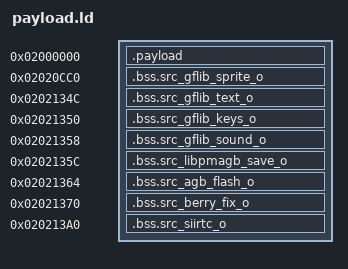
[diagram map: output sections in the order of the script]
/* Generated by ../tools/sync_layout.py; do not edit by hand. */
/* The bootstrap decompresses this image to EWRAM and branches to it. */
ENTRY(PayloadStart)
SECTIONS
{
    . = 0x02000000;
    .payload : ALIGN(4)
    {
        build/colbtl_f/asm/payload_crt0.o(.text)
        build/colbtl_f/src/main_RunLinkPartyMenu.o(.text)
        build/colbtl_f/src/main_GF_Main.o(.text)
        build/colbtl_f/src/main_RunBerryFix.o(.text)
        build/colbtl_f/src/render_text_RenderText.o(.text)
        build/colbtl_f/src/render_text_RenderText_NoPlaceholders.o(.text)
        build/colbtl_f/src/render_text_BufferString.o(.text)
        build/colbtl_f/src/render_text_GetStringWidth.o(.text)
        build/colbtl_f/src/party_menu_DrawPartyMonHealthBar.o(.text)
        build/colbtl_f/src/fade_IsScreenFadedOut.o(.text)
        build/colbtl_f/src/fade_OverrideScreenFadeState.o(.text)
        build/colbtl_f/src/fade_FadeIn.o(.text)
        build/colbtl_f/src/fade_FadeOut.o(.text)
        build/colbtl_f/src/window_DrawTextWindowBorder.o(.text)
        build/colbtl_f/src/render_text_NumToPmString3CustomZeroChar.o(.text)
        build/colbtl_f/src/window_ClearVram.o(.text)
        build/colbtl_f/src/render_text_NumToPmString3RightAlign.o(.text)
        build/colbtl_f/src/render_text_RenderTextAt.o(.text)
        build/colbtl_f/src/window_CreateTextWindow.o(.text)
        build/colbtl_f/src/party_menu_CreatePartyMonHPWindow.o(.text)
        build/colbtl_f/src/party_menu_CreateMonIcon.o(.text)
        build/colbtl_f/src/party_menu_UndoLastPartySelection.o(.text)
        build/colbtl_f/src/party_menu_CreatePartyMonIconSprite.o(.text)
        build/colbtl_f/src/party_menu_DrawPartyMonSlotLeft.o(.text)
        build/colbtl_f/src/party_menu_DrawPartyMonSlotRight.o(.text)
        build/colbtl_f/src/party_menu_PrintPartySelectionPrompt.o(.text)
        build/colbtl_f/src/party_menu_InitPartyMenu.o(.text)
        build/colbtl_f/src/party_menu_PrintPartySelectionError.o(.text)
        build/colbtl_f/src/party_menu_HandlePartyMonActionMenu.o(.text)
        build/colbtl_f/src/party_menu_HandlePartyMonSelectionMenu.o(.text)
        build/colbtl_f/src/party_menu_HandleSinglePartySelection.o(.text)
        build/colbtl_f/src/party_menu_HandleMultiPartySelection.o(.text)
        build/colbtl_f/src/party_menu_ShowPartyMenu.o(.text)
        build/colbtl_f/src/party_menu_ResetPartyMenuState.o(.text)
        build/colbtl_f/src/party_menu_ResetPartyMenuCursor.o(.text)
        build/colbtl_f/src/party_menu_BuildTwoRowMonName.o(.text)
        build/colbtl_f/src/party_menu_PutMonLvlOnWindow.o(.text)
        build/colbtl_f/src/party_menu_PutMonGenderOnBgTilemap.o(.text)
        build/colbtl_f/src/party_menu_CopyMonIconToVram.o(.text)
        build/colbtl_f/src/party_menu_ConfigurePartyMenuTilemap.o(.text)
        build/colbtl_f/src/party_menu_PrintPartySelectionOrder.o(.text)
        build/colbtl_f/src/party_menu_FindMonBySelectionOrder.o(.text)
        build/colbtl_f/src/party_menu_SendPartySelectionOrder.o(.text)
        build/colbtl_f/src/pokemon_summary_screen_InitGraphics.o(.text)
        build/colbtl_f/src/pokemon_summary_screen_CreatePartyMonFrontPic.o(.text)
        build/colbtl_f/src/pokemon_summary_screen_PrintTrainerMemoPage.o(.text)
        build/colbtl_f/src/pokemon_summary_screen_PrintMovesPage.o(.text)
        build/colbtl_f/src/pokemon_summary_screen_PrintPowerAndAccuracy.o(.text)
        build/colbtl_f/src/pokemon_summary_screen_ToggleMoveDetails.o(.text)
        build/colbtl_f/src/pokemon_summary_screen_PrintMainInfo.o(.text)
        build/colbtl_f/src/pokemon_summary_screen_TrainerMemoHandleInput.o(.text)
        build/colbtl_f/src/pokemon_summary_screen_MovesPageHandleInput.o(.text)
        build/colbtl_f/src/pokemon_summary_screen_ShowPokemonSummaryScreen.o(.text)
        build/colbtl_f/src/pokemon_summary_screen_PrintMoveDescription_.o(.text)
        build/colbtl_f/src/pokemon_summary_screen_SpriteCB_MoveSelector.o(.text)
        build/colbtl_f/src/link_message_InitLinkMessageScreen.o(.text)
        build/colbtl_f/src/link_message_PrintSaveStatusMessage.o(.text)
        build/colbtl_f/src/link_message_RunLinkStandbyLoop.o(.text)
        build/colbtl_f/src/link_message_WarningPrint.o(.text)
        build/colbtl_f/src/link_message_ErrorPrint.o(.text)
        build/colbtl_f/src/battle_menu_InitBattleMenu.o(.text)
        build/colbtl_f/src/battle_menu_CreateBattleMonSprite.o(.text)
        build/colbtl_f/src/battle_menu_PrintBattleMonGender.o(.text)
        build/colbtl_f/src/battle_menu_DrawBattleMonInfo.o(.text)
        build/colbtl_f/src/battle_menu_PrintMenuOptions.o(.text)
        build/colbtl_f/src/battle_menu_HandleMenuInput.o(.text)
        build/colbtl_f/src/battle_menu_PrintMoveTypeAndPP.o(.text)
        build/colbtl_f/src/battle_menu_DrawMoveSelectionMenu.o(.text)
        build/colbtl_f/src/battle_menu_FormatLinkMonName.o(.text)
        build/colbtl_f/src/battle_menu_DrawTargetSelectionMenu.o(.text)
        build/colbtl_f/src/battle_menu_ConfirmGiveIn.o(.text)
        build/colbtl_f/src/battle_menu_PrintBattleMenuMessage.o(.text)
        build/colbtl_f/src/battle_menu_ShowBattleMenu.o(.text)
        build/colbtl_f/src/link_transfer_ApplyLinkBattlePartyData.o(.text)
        build/colbtl_f/src/battle_menu_ShowBattleMonMessage.o(.text)
        build/colbtl_f/src/battle_menu_RestoreBattleMenu.o(.text)
        build/colbtl_f/src/battle_menu_RestoreTargetMenu.o(.text)
        build/colbtl_f/src/battle_menu_BufferSelectedMoveName.o(.text)
        build/colbtl_f/src/battle_menu_ValidateSelectedMove.o(.text)
        build/colbtl_f/src/link_transfer_FinalizeLinkSave.o(.text)
        build/colbtl_f/src/link_transfer_FinalizeCouponTransfer.o(.text)
        build/colbtl_f/src/link_transfer_FinalizePokemonTransfer.o(.text)
        build/colbtl_f/src/link_transfer_BufferFirstPartyMon.o(.text)
        build/colbtl_f/src/link_transfer_GetSwitchOutRestriction.o(.text)
        build/colbtl_f/src/battle_menu_GetMoveRestriction.o(.text)
        build/colbtl_f/src/battle_menu_IsMoveSelectionLocked.o(.text)
        build/colbtl_f/src/battle_menu_GetBattleMenuRestriction.o(.text)
        build/colbtl_f/src/battle_menu_GetForcedMoveSlot.o(.text)
        build/colbtl_f/src/battle_menu_IsMonFainted.o(.text)
        build/colbtl_f/src/link_transfer_GetLinkSelectedMonId.o(.text)
        build/colbtl_f/src/link_transfer_ShouldUseLinkPartyMenu.o(.text)
        build/colbtl_f/src/link_transfer_GetNibbleByIndex.o(.text)
        build/colbtl_f/src/link_transfer_IsPartySlotOccupied.o(.text)
        build/colbtl_f/asm/m4a_1.o(.text)
        build/colbtl_f/src/m4a.o(.text)
        build/colbtl_f/src/gflib/init.o(.text)
        build/colbtl_f/src/gflib/bg.o(.text)
        build/colbtl_f/src/gflib/sprite.o(.text)
        build/colbtl_f/src/gflib/text.o(.text)
        build/colbtl_f/src/gflib/keys.o(.text)
        build/colbtl_f/src/gflib/decompress.o(.text)
        build/colbtl_f/src/gflib/sound.o(.text)
        build/colbtl_f/src/libpmagb/save_block_pointers.o(.text)
        build/colbtl_f/src/libpmagb/pic_uncomp.o(.text)
        build/colbtl_f/src/libpmagb/save.o(.text)
        build/colbtl_f/src/pokemon_2_GetSubstruct.o(.text)
        build/colbtl_f/src/pokemon_1_CalculateBoxMonChecksum.o(.text)
        build/colbtl_f/src/pokemon_4_GetBoxMonData.o(.text)
        build/colbtl_f/src/get_party_mon_pal_GetPartyMonSpritePalStruct.o(.text)
        build/colbtl_f/src/get_mon_ability_GetBoxMonAbility.o(.text)
        build/colbtl_f/src/ball_gfx_BoxMonGetCaughtBallItemSpriteSheet.o(.text)
        build/colbtl_f/src/ball_gfx_BoxMonGetCaughtBallItemPalette.o(.text)
        build/colbtl_f/src/mon_move_pp_GetBoxMonMoveBySlot.o(.text)
        build/colbtl_f/src/mon_move_pp_GetBoxMonPPByMoveSlot.o(.text)
        build/colbtl_f/src/pokemon_pokerus_CheckPartyPokerus.o(.text)
        build/colbtl_f/src/pokemon_pokerus_GetMonAilment.o(.text)
        build/colbtl_f/src/pokemon_pokerus_CheckPartyHasHadPokerus.o(.text)
        build/colbtl_f/src/spinda_DrawSpindaSpots.o(.text)
        build/colbtl_f/src/pokemon_5_SetBoxMonData.o(.text)
        build/colbtl_f/src/set_mon_data_SetMonData.o(.text)
        build/colbtl_f/src/give_ribbon_GiveGiftRibbonToParty.o(.text)
        build/colbtl_f/src/pokemon_3_GetMonData.o(.text)
        build/colbtl_f/src/mon_gender_GetBoxMonGender.o(.text)
        build/colbtl_f/src/mon_sprite_icon_GetMonSpritePalStructFromOtIdPersonality.o(.text)
        build/colbtl_f/src/mon_sprite_icon_GetIconSpecies.o(.text)
        build/colbtl_f/src/species_name_GetSpeciesName.o(.text)
        build/colbtl_f/src/mon_data_lookups_GetMonType.o(.text)
        build/colbtl_f/src/mon_data_lookups_GetTypePaletteNum.o(.text)
        build/colbtl_f/src/mon_data_lookups_GetAbilityName.o(.text)
        build/colbtl_f/src/mon_data_lookups_GetAbilityDescription.o(.text)
        build/colbtl_f/src/mon_data_lookups_CalculatePPWithBonus.o(.text)
        build/colbtl_f/src/move_name_CopyMoveName.o(.text)
        build/colbtl_f/src/get_party_slot_GetPtrToEmptyPartySlot.o(.text)
        build/colbtl_f/src/get_mon_gender_GetMonGender.o(.text)
        build/colbtl_f/src/mon_sprite_icon_GetUnownLetterByPersonality.o(.text)
        build/colbtl_f/src/libpmagb/berry_GetEnigmaBerryChecksum.o(.text)
        build/colbtl_f/src/libpmagb/berry_IsEnigmaBerryValid.o(.text)
        build/colbtl_f/src/libpmagb/berry_GetBerryInfo.o(.text)
        build/colbtl_f/src/libpmagb/berry_GetItemName.o(.text)
        build/colbtl_f/src/libpmagb/berry_CopyItemName.o(.text)
        build/colbtl_f/src/libpmagb/item_id_remap_ItemIdToBallId.o(.text)
        build/colbtl_f/src/libpmagb/pokedex_GetSetPokedexFlag.o(.text)
        build/colbtl_f/src/libpmagb/pokedex_SpeciesToNationalPokedexNum.o(.text)
        build/colbtl_f/src/libpmagb/pokedex_SetSpeciesCaughtFlag.o(.text)
        build/colbtl_f/src/player_record_SetPlayerLinkInfo.o(.text)
        build/colbtl_f/src/player_record_GetPlayerLinkInfo.o(.text)
        build/colbtl_f/src/player_record_GetTextBufferPointer.o(.text)
        build/colbtl_f/src/joybus_recv_SetLinkCommandReady.o(.text)
        build/colbtl_f/src/joybus_recv_IsLinkCommandReady.o(.text)
        build/colbtl_f/src/libpmagb/flag_FlagSet.o(.text)
        build/colbtl_f/src/libpmagb/flag_FlagClear.o(.text)
        build/colbtl_f/src/libpmagb/flag_FlagGet.o(.text)
        build/colbtl_f/src/libpmagb/target_game_DetectROM.o(.text)
        build/colbtl_f/src/libpmagb/target_game_GetPlayerMapType.o(.text)
        build/colbtl_f/src/libpmagb/target_game_EmptyFunction.o(.text)
        build/colbtl_f/src/libpmagb/target_game_CheckIfPokedexIsObtained.o(.text)
        build/colbtl_f/src/libpmagb/target_game_IsFRLG.o(.text)
        build/colbtl_f/src/libpmagb/target_game_CheckGameClear.o(.text)
        build/colbtl_f/src/libpmagb/string_util_StringLength.o(.text)
        build/colbtl_f/src/libpmagb/string_util_StringCopy.o(.text)
        build/colbtl_f/src/libpmagb/string_util_StringAppend.o(.text)
        build/colbtl_f/src/libpmagb/string_util_StringCompare.o(.text)
        build/colbtl_f/src/libpmagb/string_util_GetExtCtrlCodeLength.o(.text)
        build/colbtl_f/src/libpmagb/map_check_GetRSPlayerMapType.o(.text)
        build/colbtl_f/src/joybus_recv_mon_ReceivePartyMon.o(.text)
        build/colbtl_f/src/joybus_recv_ReceiveMonData.o(.text)
        build/colbtl_f/src/joybus_recv_ReceiveGiftData.o(.text)
        build/colbtl_f/src/joybus_recv_ProcessReceiveCommand.o(.text)
        build/colbtl_f/src/joybus_cmd_TransmitGiftData.o(.text)
        build/colbtl_f/src/joybus_cmd_ProcessTransmitCommand.o(.text)
        build/colbtl_f/src/joybus_cmd_JoyBusVCountIntr.o(.text)
        build/colbtl_f/src/joybus_init_InitJoyBus.o(.text)
        build/colbtl_f/src/joybus_init_InitLink.o(.text)
        build/colbtl_f/src/joybus_wait_VBlankCB.o(.text)
        build/colbtl_f/src/joybus_recv_CopyBytes.o(.text)
        build/colbtl_f/src/agb_flash.o(.text)
        build/colbtl_f/src/agb_flash_1m.o(.text)
        build/colbtl_f/src/agb_flash_mx.o(.text)
        build/colbtl_f/src/berry_fix.o(.text)
        build/colbtl_f/src/siirtc.o(.text)
        build/colbtl_f/asm/payload_bios.o(.text)
        build/colbtl_f/libgcc/_call_via_rX.o(.text)
        build/colbtl_f/libgcc/_divsi3.o(.text)
        build/colbtl_f/libgcc/_dvmd_tls.o(.text)
        build/colbtl_f/libgcc/_modsi3.o(.text)
        build/colbtl_f/libgcc/_umodsi3.o(.text)
        build/colbtl_f/src/libpmagb/libc.o(.text)
        build/colbtl_f/src/font_window.o(.rodata)
        build/colbtl_f/data/font0_latin.o(.rodata)
        build/colbtl_f/data/font1_latin.o(.rodata)
        build/colbtl_f/data/font0_japanese.o(.rodata)
        build/colbtl_f/data/font1_japanese.o(.rodata)
        build/colbtl_f/src/gfx_title_gfx.o(.rodata)
        build/colbtl_f/src/gfx_title_pal.o(.rodata)
        build/colbtl_f/src/gfx_title_tilemap.o(.rodata)
        build/colbtl_f/src/gfx_title_extra_pal.o(.rodata)
        build/colbtl_f/src/gfx_mon_info_icons.o(.rodata)
        build/colbtl_f/src/gfx_party_menu.o(.rodata)
        build/colbtl_f/src/gfx_message_box.o(.rodata)
        build/colbtl_f/src/gfx_text_pal.o(.rodata)
        build/colbtl_f/src/gfx_party_menu_tilemap.o(.rodata)
        build/colbtl_f/src/gfx_party_slots_tilemap.o(.rodata)
        build/colbtl_f/src/gfx_summary_screen.o(.rodata)
        build/colbtl_f/src/gfx_summary_icons.o(.rodata)
        build/colbtl_f/src/gfx_summary_pal.o(.rodata)
        build/colbtl_f/src/gfx_summary_skills_tilemap.o(.rodata)
        build/colbtl_f/src/gfx_summary_moves_tilemap.o(.rodata)
        build/colbtl_f/src/gfx_type_status_icons.o(.rodata)
        build/colbtl_f/src/gfx_type_status_pal.o(.rodata)
        build/colbtl_f/src/gfx_battle_screen.o(.rodata)
        build/colbtl_f/src/gfx_battle_pal.o(.rodata)
        build/colbtl_f/src/gfx_battle_tilemap.o(.rodata)
        build/colbtl_f/src/gfx_battle_windows_tilemap.o(.rodata)
        build/colbtl_f/src/m4a_tables.o(.rodata)
        build/colbtl_f/data/sound_data.o(.rodata)
        build/colbtl_f/src/pokemon_tables_gSpindaSpotGraphics.o(.rodata)
        build/colbtl_f/src/pokemon_tables_gText_Egg.o(.rodata)
        build/colbtl_f/src/berries_gBerries.o(.rodata)
        build/colbtl_f/src/pokemon_tables_gBitTable.o(.rodata)
        build/colbtl_f/src/pokemon_tables_gTypeToPaletteNumber.o(.rodata)
        build/colbtl_f/src/pokemon_tables_gPPUpGetMask.o(.rodata)
        build/colbtl_f/src/pokemon_tables_gGiftRibbonMonDataIds.o(.rodata)
        . += 0x2;
        build/colbtl_f/src/pokemon_tables_gSpeciesToNationalPokedexNum.o(.rodata)
        . += 0x2;
        build/colbtl_f/src/text_gExtCtrlCodeLengths.o(.rodata)
        build/colbtl_f/src/maps_gRSPokemonCenterMaps.o(.rodata)
        build/colbtl_f/src/maps_gRSLobbyMaps.o(.rodata)
        build/colbtl_f/src/agb_flash.o(.rodata)
        build/colbtl_f/src/agb_flash_1m.o(.rodata)
        build/colbtl_f/src/agb_flash_mx.o(.rodata)
        build/colbtl_f/src/agb_flash_le.o(.rodata)
        build/colbtl_f/src/berry_fix.o(.rodata)
        build/colbtl_f/src/siirtc.o(.rodata)
        build/colbtl_f/data/ui_data.o(.data)
        . += 0x1;
        build/colbtl_f/src/strings.o(.data)
        build/colbtl_f/src/libpmagb/save.o(.data)
        build/colbtl_f/src/bad_egg.o(.rodata)
        build/colbtl_f/src/target_games_regional.o(.data)
    }

    __payload_end = .;
    ASSERT(__payload_end == 0x02020A30, "payload size changed")

    .bss.src_gflib_sprite_o 0x02020CC0 (NOLOAD) : { build/colbtl_f/src/gflib/sprite.o(.bss) }
    .bss.src_gflib_text_o 0x0202134C (NOLOAD) : { build/colbtl_f/src/gflib/text.o(.bss) }
    .bss.src_gflib_keys_o 0x02021350 (NOLOAD) : { build/colbtl_f/src/gflib/keys.o(.bss) }
    .bss.src_gflib_sound_o 0x02021358 (NOLOAD) : { build/colbtl_f/src/gflib/sound.o(.bss) }
    .bss.src_libpmagb_save_o 0x0202135C (NOLOAD) : { build/colbtl_f/src/libpmagb/save.o(.bss) }
    .bss.src_agb_flash_o 0x02021364 (NOLOAD) : { build/colbtl_f/src/agb_flash.o(.bss) }
    .bss.src_berry_fix_o 0x02021370 (NOLOAD) : { build/colbtl_f/src/berry_fix.o(.bss) }
    .bss.src_siirtc_o 0x020213A0 (NOLOAD) : { build/colbtl_f/src/siirtc.o(.bss) }

    /* Data these objects emit is still covered by the raw ranges. */
    /DISCARD/ :
    {
        *(.rodata)
        *(.data)
        *(.comment)
        *(.ARM.attributes)
        *(.note.*)
    }
}
